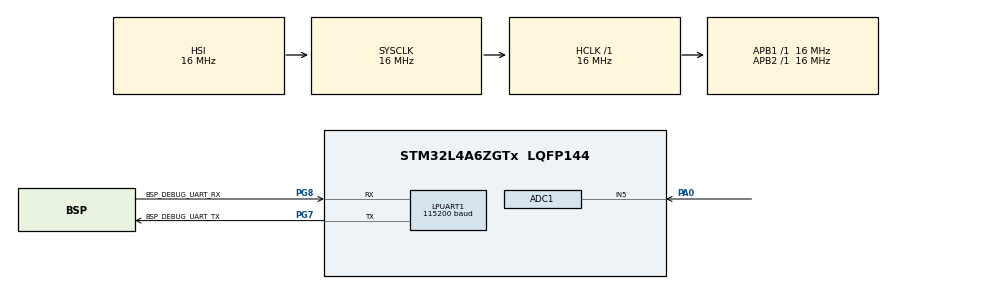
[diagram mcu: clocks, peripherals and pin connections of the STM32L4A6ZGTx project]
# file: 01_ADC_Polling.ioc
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ADC1.Channel-2\#ChannelRegularConversion=ADC_CHANNEL_5
ADC1.ContinuousConvMode=DISABLE
ADC1.NbrOfConversionFlag=1
ADC1.OffsetNumber-2\#ChannelRegularConversion=ADC_OFFSET_NONE
ADC1.Rank-2\#ChannelRegularConversion=1
ADC1.SamplingTime-2\#ChannelRegularConversion=ADC_SAMPLETIME_2CYCLES_5
ADC1.master=1
LPUART1.BaudRate=115200
LPUART1.WordLength=UART_WORDLENGTH_8B
Mcu.Family=STM32L4
Mcu.Name=STM32L4A6ZGTx
Mcu.Package=LQFP144
NVIC.PriorityGroup=NVIC_PRIORITYGROUP_4
PA0.Signal=ADCx_IN5
PG7.GPIO_Label=BSP_DEBUG_UART_TX
PG7.Mode=Asynchronous
PG7.Signal=LPUART1_TX
PG8.GPIO_Label=BSP_DEBUG_UART_RX
PG8.Mode=Asynchronous
PG8.Signal=LPUART1_RX
ProjectManager.HeapSize=0x200
ProjectManager.StackSize=0x400
ProjectManager.TargetToolchain=STM32CubeIDE
RCC.ADCFreq_Value=12000000
RCC.AHBFreq_Value=16000000
RCC.APB1Freq_Value=16000000
RCC.APB1TimFreq_Value=16000000
RCC.APB2Freq_Value=16000000
RCC.APB2TimFreq_Value=16000000
RCC.CortexFreq_Value=16000000
RCC.HCLKFreq_Value=16000000
RCC.HSE_VALUE=8000000
RCC.HSI48_VALUE=48000000
RCC.HSI_VALUE=16000000
RCC.LSE_VALUE=32768
RCC.MSI_VALUE=4000000
RCC.PLLM=2
RCC.PLLSAI1N=9
RCC.PLLSAI1R=RCC_PLLR_DIV6
RCC.PLLSourceVirtual=RCC_PLLSOURCE_HSI
RCC.SYSCLKFreq_VALUE=16000000
RCC.SYSCLKSource=RCC_SYSCLKSOURCE_HSI
RCC.USBFreq_Value=36000000
RCC.VCOOutputFreq_Value=64000000
SH.ADCx_IN5.0=ADC1_IN5,IN5-Single-Ended
board=NUCLEO-L4A6ZG

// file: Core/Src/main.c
/* USER CODE BEGIN Header */
/**
  ******************************************************************************
  * @file           : main.c
  * @brief          : Main program body
  ******************************************************************************
  * @attention
  *
  * Copyright (c) 2024 STMicroelectronics.
  * All rights reserved.
  *
  * This software is licensed under terms that can be found in the LICENSE file
  * in the root directory of this software component.
  * If no LICENSE file comes with this software, it is provided AS-IS.
  *
  ******************************************************************************
  */
/* USER CODE END Header */
#include "main.h"

/* USER CODE BEGIN Includes */
#include "stdio.h"
/* USER CODE END Includes */

/* USER CODE BEGIN PM */
#define V_REF 3.3
/* USER CODE END PM */

ADC_HandleTypeDef hadc1;

UART_HandleTypeDef hlpuart1;

/* USER CODE BEGIN PV */

uint32_t adc_val;
float analog_voltage;

/* USER CODE END PV */

void SystemClock_Config(void);
static void MX_GPIO_Init(void);
static void MX_ADC1_Init(void);
static void MX_LPUART1_UART_Init(void);

int main(void)
{

  /* MCU Configuration--------------------------------------------------------*/

  /* Reset of all peripherals, Initializes the Flash interface and the Systick. */
  HAL_Init();

  /* Configure the system clock */
  SystemClock_Config();

  /* Initialize all configured peripherals */
  MX_GPIO_Init();
  MX_ADC1_Init();
  MX_LPUART1_UART_Init();

  /* Infinite loop */
  while (1)
  {

    /* USER CODE BEGIN 3 */

	  HAL_ADC_Start(&hadc1);						//start the adc
	  HAL_ADC_PollForConversion(&hadc1, 1000);		//wait for converion
	  adc_val = HAL_ADC_GetValue(&hadc1);			//get the digital value

	  HAL_ADC_Stop(&hadc1);							//stop the adc

	  HAL_Delay(1000);								//wait for some time

	  analog_voltage = ((adc_val/4095.0) * 3.3);	//get the analog voltage value
	  printf("Adc Value: %ld, Analog Voltage: %.2f V\r\n", adc_val, analog_voltage);	//print the value

  }
  /* USER CODE END 3 */
}

void SystemClock_Config(void)
{
  RCC_OscInitTypeDef RCC_OscInitStruct = {0};
  RCC_ClkInitTypeDef RCC_ClkInitStruct = {0};

  /** Configure the main internal regulator output voltage
  */
  if (HAL_PWREx_ControlVoltageScaling(PWR_REGULATOR_VOLTAGE_SCALE1) != HAL_OK)
  {
    Error_Handler();
  }

  /** Initializes the RCC Oscillators according to the specified parameters
  * in the RCC_OscInitTypeDef structure.
  */
  RCC_OscInitStruct.OscillatorType = RCC_OSCILLATORTYPE_HSI;
  RCC_OscInitStruct.HSIState = RCC_HSI_ON;
  RCC_OscInitStruct.HSICalibrationValue = RCC_HSICALIBRATION_DEFAULT;
  RCC_OscInitStruct.PLL.PLLState = RCC_PLL_NONE;
  if (HAL_RCC_OscConfig(&RCC_OscInitStruct) != HAL_OK)
  {
    Error_Handler();
  }

  /** Initializes the CPU, AHB and APB buses clocks
  */
  RCC_ClkInitStruct.ClockType = RCC_CLOCKTYPE_HCLK|RCC_CLOCKTYPE_SYSCLK
                              |RCC_CLOCKTYPE_PCLK1|RCC_CLOCKTYPE_PCLK2;
  RCC_ClkInitStruct.SYSCLKSource = RCC_SYSCLKSOURCE_HSI;
  RCC_ClkInitStruct.AHBCLKDivider = RCC_SYSCLK_DIV1;
  RCC_ClkInitStruct.APB1CLKDivider = RCC_HCLK_DIV1;
  RCC_ClkInitStruct.APB2CLKDivider = RCC_HCLK_DIV1;

  if (HAL_RCC_ClockConfig(&RCC_ClkInitStruct, FLASH_LATENCY_0) != HAL_OK)
  {
    Error_Handler();
  }
}

static void MX_ADC1_Init(void)
{

  ADC_MultiModeTypeDef multimode = {0};
  ADC_ChannelConfTypeDef sConfig = {0};

  /** Common config
  */
  hadc1.Instance = ADC1;
  hadc1.Init.ClockPrescaler = ADC_CLOCK_ASYNC_DIV1;
  hadc1.Init.Resolution = ADC_RESOLUTION_12B;
  hadc1.Init.DataAlign = ADC_DATAALIGN_RIGHT;
  hadc1.Init.ScanConvMode = ADC_SCAN_DISABLE;
  hadc1.Init.EOCSelection = ADC_EOC_SINGLE_CONV;
  hadc1.Init.LowPowerAutoWait = DISABLE;
  hadc1.Init.ContinuousConvMode = DISABLE;
  hadc1.Init.NbrOfConversion = 1;
  hadc1.Init.DiscontinuousConvMode = DISABLE;
  hadc1.Init.ExternalTrigConv = ADC_SOFTWARE_START;
  hadc1.Init.ExternalTrigConvEdge = ADC_EXTERNALTRIGCONVEDGE_NONE;
  hadc1.Init.DMAContinuousRequests = DISABLE;
  hadc1.Init.Overrun = ADC_OVR_DATA_PRESERVED;
  hadc1.Init.OversamplingMode = DISABLE;
  if (HAL_ADC_Init(&hadc1) != HAL_OK)
  {
    Error_Handler();
  }

  /** Configure the ADC multi-mode
  */
  multimode.Mode = ADC_MODE_INDEPENDENT;
  if (HAL_ADCEx_MultiModeConfigChannel(&hadc1, &multimode) != HAL_OK)
  {
    Error_Handler();
  }

  /** Configure Regular Channel
  */
  sConfig.Channel = ADC_CHANNEL_5;
  sConfig.Rank = ADC_REGULAR_RANK_1;
  sConfig.SamplingTime = ADC_SAMPLETIME_2CYCLES_5;
  sConfig.SingleDiff = ADC_SINGLE_ENDED;
  sConfig.OffsetNumber = ADC_OFFSET_NONE;
  sConfig.Offset = 0;
  if (HAL_ADC_ConfigChannel(&hadc1, &sConfig) != HAL_OK)
  {
    Error_Handler();
  }

}

static void MX_LPUART1_UART_Init(void)
{

  hlpuart1.Instance = LPUART1;
  hlpuart1.Init.BaudRate = 115200;
  hlpuart1.Init.WordLength = UART_WORDLENGTH_8B;
  hlpuart1.Init.StopBits = UART_STOPBITS_1;
  hlpuart1.Init.Parity = UART_PARITY_NONE;
  hlpuart1.Init.Mode = UART_MODE_TX_RX;
  hlpuart1.Init.HwFlowCtl = UART_HWCONTROL_NONE;
  hlpuart1.Init.OneBitSampling = UART_ONE_BIT_SAMPLE_DISABLE;
  hlpuart1.AdvancedInit.AdvFeatureInit = UART_ADVFEATURE_NO_INIT;
  if (HAL_UART_Init(&hlpuart1) != HAL_OK)
  {
    Error_Handler();
  }

}

static void MX_GPIO_Init(void)
{

  /* GPIO Ports Clock Enable */
  __HAL_RCC_GPIOA_CLK_ENABLE();
  __HAL_RCC_GPIOG_CLK_ENABLE();
  HAL_PWREx_EnableVddIO2();

}

void Error_Handler(void)
{
  __disable_irq();
  while (1)
  {
  }
}
